# tviic2d6mddr register map
Vendor: Cypress Semiconductor; Series: tviic2d6mddr; File version: 1.0
CPU: CM7 r0p1, little endian, MPU, FPU, VTOR, 3 interrupt priority bits
Registers are 32-bit, read-write, reset 0x0 unless marked. A register's access mark holds for its fields unless they carry their own. Offsets are from the block's base; [hi:lo] are bit positions; lines under a group give offsets from that group; {n}, {i} and the like mark numbered series; 'fields as' and 'values as' point back to an identical list; <NAME> marks a mode.

## MIXER0 — MIXER
Base 0x40880000
Same registers: MIXER1 0x40890000
{0x8000+0x100*i} MIXER_SRC_STRUCT[{i}] (i=0..4) group — Mixer source structure
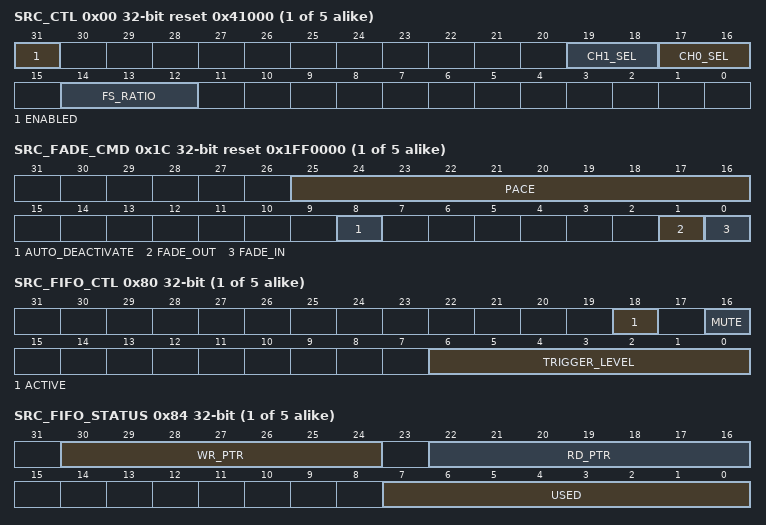
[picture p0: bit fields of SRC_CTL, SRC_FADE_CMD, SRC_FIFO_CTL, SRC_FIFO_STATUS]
  0x00 SRC_CTL reset 0x41000 — Source control
    [31] ENABLED — Source enable: '0': Disabled. All non-retained MMIO registers (e.g. the SRC_STATUS, SRC_FIFO_STATUS and INTR_SRC registers) have their fields reset to their default value. '1': Enabled. Note: when all sources, destination and transmitter are disabled, the SRAMs are driven into low power mode, if supported by the SRAM. When exiting such low power mode software needs to allow for a certain power up time before SRAM can be used, i.e. before ACTIVE can be asserted. The power up time is equivalent to the system SRAM power up time specified in the CPUSS.RAM_PWR_DELAY_CTL register (or equivalent for platforms other than MXS40).
    [19:18] CH1_SEL — Channel selection. Specifies selection of the channel's 16-bit PCM data from the source FIFO data[31:0]: '0': data[15:0]. '1': data[31:16] (default setting). '2': Constant PCM data value of '0'; i.e. source FIFO data is not used. '3': undefined.
      0=DATA_LOW (N/A); 1=DATA_HIGH (N/A); 2=CONSTANT_0 (N/A)
    [17:16] CH0_SEL — Channel selection. Specifies selection of the channel's 16-bit PCM data from the source FIFO data[31:0]: '0': data[15:0] (default setting). '1': data[31:16]. '2': Constant PCM data value of '0'; i.e. source FIFO data is not used. '3': undefined. Note: CH0_SEL and CH1_SEL are used to specify mono and stereo audio formats.
      0=DATA_LOW (N/A); 1=DATA_HIGH (N/A); 2=CONSTANT_0 (N/A)
    [14:12] FS_RATIO — Sample frequency upscale ratio: '0': 0.5 (downsampling by 2x). '1': 1 (no resampling). '2': 2 (upsampling by 2x). '3': 3. '4': 4. '5': 6. '6': 8. '7': 12 (upsampling by 12x).
      0=DOWN_2 (N/A); 1=SAME (N/A); 2=UP_2 (N/A); 3=UP_3 (N/A); 4=UP_4 (N/A); 5=UP_6 (N/A); 6=UP_8 (N/A); 7=UP_12 (N/A)
  0x04 SRC_STATUS ro — Source status
    [3:0] PHASE — Current FIR phase value. A upscale ratio of 'n' uses a n polyphase FIR filter. The phases are numbered [0, n-1].
      0=N/A; 1=N/A; 11=N/A
  0x14 SRC_FADE_CTL reset 0x73 — Source fade control
    [6:0] CODE — Gain code in the range [0, 115]. See SRC_GAIN_CTL.CODE[]. Note: HW modifies this field during 'fade in' and 'fade out'. For 'fade in' HW will gradually increment the value until it reaches '115'. For 'fade out' HW will gradually decrement the value until it reaches '0'. Note: SW is typically required to reprogram the CODE field in between successive 'fade in' operations or in between successive 'fade out' operations.
  0x18 SRC_FADE_STATUS ro reset not defined — Source fade status
    [25:16] PACE — Current fading pace counter value. SRC_FADE_CTL.PACE value of 'n' reuses a specific fade value 'n+1' times. The reuses are numbered [0, n].
  0x1C SRC_FADE_CMD reset 0x1FF0000 — Source fade command
    [25:16] PACE — Specifies the pace/speed of 'fade in' and 'fade out': '0': The same CODE value is used (0+1) times. '1': The same CODE value is used (1+1) times. ... '1023': The same CODE value is used (1023+1) times. A fade in from 'mute' to 0 dB takes 1024*116 = 118,784 PCM samples. At a PCM sample frequency Fs of 48 kHz, this translates into 118,784/48,000 = 2.474 seconds.
    [8] AUTO_DEACTIVATE — Specifies behavior when 'fade out' has completed: '0': Source does NOT get deactivated. '1': Source gets deactivated; i.e. HW clears SRC_FIFO_CTL.ACTIVE to '0'.
    [1] FADE_OUT — 'Fade out' functionality: '0': Disabled. '1': Enabled: Changes CODE gradually to '0' (digital mute). Typically, SW sets this field to '1' to start 'fade out' functionality. HW clears this field to '0' to indicate that 'fade out' has completed; i.e. 'muting' is achieved. Note: FADE_IN and FADE_OUT should be used mutually exclusively. However, if 'fade in' is desired while 'fading out', SW can set FADE_IN to '1' and clear FADE_OUT to '0'. 'Fade in' will commence from the current CODE value. Similarly, if 'fade out' is desired while 'fading in', SW can set FADE_OUT to '1' and clear FADE_IN to '0'. 'Fade out' will commence from the current CODE value.
    [0] FADE_IN — 'Fade in' functionality: '0': Disabled. '1': Enabled: Increments CODE gradually to '115'. Typically, SW sets this field to '1' to start 'fade in' functionality. HW clears this field to '0' to indicate that 'fade in' has completed; i.e. 0 dB amplification is achieved.
  0x20 SRC_GAIN_CTL reset 0x73 — Source gain control
    [6:0] CODE — Gain code in the range [0, 127]. Each gain code increment represents 1 dB. Gain code value '0' represents digital mute. Gain code '127' represents a maximum amplification of 12 dB. The gain code is used to derive a multipler value (in the range [0, 8191]) and shift value (in the range [11, 26]). '0': digital mute. Multiplier value is '0' and 'shift' is '26'. '1': -114 dB. Multiplier value is '134' and 'shift' is '26'. '2': -113 dB. Multiplier value is '150' and 'shift' is '26'. '3': -112 dB. Multiplier value is '169' and 'shift' is '26'. ... '115': 0 dB. Multiplier value is '4096' and 'shift' is '12'. Note that (4096 * x) >> 12 = x; i.e. the PCM value is unaffected. ... '121': 6 dB. Multiplier value is '8173' and 'shift' is '12'. ... '127': 12 dB. Multiplier value is '8153' and 'shift' is '11'. gc_pcm[15:0] = CLIP16 ((multiplier[12:0]*fir_scaled_pcm[15:0]) >> shift)
  0x80 SRC_FIFO_CTL — Source FIFO control
    [18] ACTIVE — Activate functionality: '0': Mixer source inactive; i.e. use PCM data value of '0'. '1': Mixer source active; i.e. use FIFO PCM data, when PCM data are not available: wait. HW clears this field to '0' when fading out has completed and SRC_FADE_CMD.AUTO_DEACTIVATE is '1'. Note: This functionality is intended for startup purposes. To start the mixer, SW should first activate the sources(s) and second activate the destination. To stop the mixer, SW should first deactivate the destination and second deactivate the source(s).
    [16] MUTE — Mute functionality: '0': Mixer source unmuted; i.e. source FIFO data. '1': Mixer source muted; i.e. use PCM data value of '0'. Mute does advance the FIFO read pointer. Note: HW ensures that mute functionality synchronizes on the first channel of a frame to ensure that either all or none of the frame's channels are muted.
    [6:0] TRIGGER_LEVEL — Trigger level. When the source FIFO has less entries than the number of this field, a transmitter trigger event is generated: - INTR_SRC.FIFO_TRIGGER = (# FIFO entries < TRIGGER_LEVEL)
  0x84 SRC_FIFO_STATUS ro — Source FIFO status
    [30:24] WR_PTR — Source FIFO write pointer: Source FIFO location at which a new data is written by the hardware. Note: This functionality is intended for debugging purposes.
    [22:16] RD_PTR — Source FIFO read pointer: Source FIFO location from which a data is read. Note: This functionality is intended for debugging purposes.
    [7:0] USED — Number of used/occupied entries in the source FIFO. The field value is in the range [0, 128]. When '0', the FIFO is empty. When '128', the FIFO is full. Note: A source FIFO has double the capacity of the destination FIFO. This is because the sample frequency conversion requires 63 PCM input samples to produce a PCM output sample (63-taps FIR filter).
  0x88 SRC_FIFO_WR wo — Source FIFO write
    [31:0] DATA — Data (PCM sample pair of two 16-bit samples) written to the top source FIFO entry (data[31:0] = DATA[31:0]). Typically, DATA[15:0] is used for channel 0 and DATA[31:16] is used for channel 1. Writing adds the data to the source FIFO; i.e. behavior is similar to that of a PUSH operation (SRC_FIFO_STATUS.WR_PTR is incremented and SRC_FIFO_STATUS.USED is incremented). Note: Writing to a full source FIFO activates INTR_SRC.FIFO_OVERFLOW.
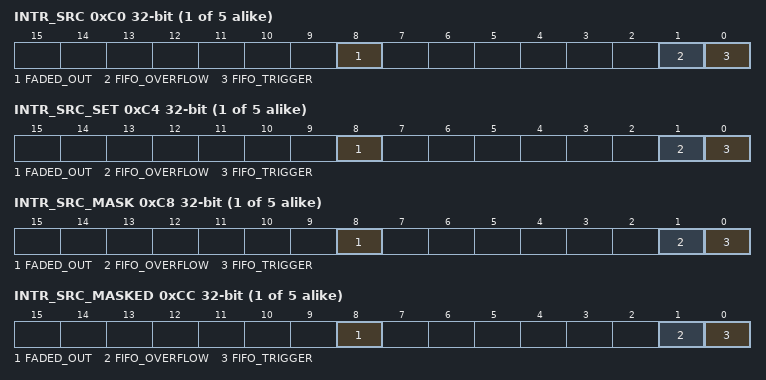
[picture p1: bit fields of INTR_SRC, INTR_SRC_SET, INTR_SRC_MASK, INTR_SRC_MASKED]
  0xC0 INTR_SRC — Interrupt
    [8] FADED_OUT — HW sets this field to '1', when fade out has completed (HW changes SRC_FADE_CMD.FADE_OUT from '0' to '1').
    [1] FIFO_OVERFLOW — HW sets this field to '1', when writing to a full source FIFO (SRC_FIFO_STATUS.USED is '128').
    [0] FIFO_TRIGGER — HW sets this field to '1', when a source trigger is generated.
  0xC4 INTR_SRC_SET — Interrupt set
    [8] FADED_OUT — Write this field with '1' to set corresponding INTR_SRC field (a write of '0' has no effect).
    [1] FIFO_OVERFLOW — Write this field with '1' to set corresponding INTR_SRC field (a write of '0' has no effect).
    [0] FIFO_TRIGGER — Write this field with '1' to set corresponding INTR_SRC field (a write of '0' has no effect).
  0xC8 INTR_SRC_MASK — Interrupt mask
    [8] FADED_OUT — Mask for corresponding field in INTR_SRC register.
    [1] FIFO_OVERFLOW — Mask for corresponding field in INTR_SRC register.
    [0] FIFO_TRIGGER — Mask for corresponding field in INTR_SRC register.
  0xCC INTR_SRC_MASKED ro — Interrupt masked
    [8] FADED_OUT — Logical AND of corresponding INTR_SRC and INTR_SRC_MASK fields.
    [1] FIFO_OVERFLOW — Logical AND of corresponding INTR_SRC and INTR_SRC_MASK fields.
    [0] FIFO_TRIGGER — Logical AND of corresponding INTR_SRC and INTR_SRC_MASK fields.
0xC000 MIXER_DST_STRUCT group — Mixer destination structure
  0x00 DST_CTL — Destination control
    [31] ENABLED — Destination enable: '0': Disabled. All non-retained MMIO registers (e.g. the DST_FADE_STATUS, DST_FIFO_STATUS and INTR_DST registers) have their fields reset to their default value. '1': Enabled. Note: when all sources, destination and transmitter are disabled, the SRAMs are driven into low power mode, if supported by the SRAM. When exiting such low power mode software needs to allow for a certain power up time before SRAM can be used, i.e. before ACTIVE can be asserted. The power up time is equivalent to the system SRAM power up time specified in the CPUSS.RAM_PWR_DELAY_CTL register (or equivalent for platforms other than MXS40).
  0x14 DST_FADE_CTL reset 0x73 — Destination fade control
    [6:0] CODE — Gain code in the range [0, 115]. See DST_GAIN_CTL.CODE[]. Note: HW modifies this field during 'fade in' and 'fade out'. For 'fade in' HW will gradually increment the value until it reaches '115'. For 'fade out' HW will gradually decrement the value until it reaches '0'. Note: SW is typically required to reprogram the CODE field in between successive 'fade in' operations or in between successive 'fade out' operations.
  0x18 DST_FADE_STATUS ro reset not defined — Destination fade status
    [25:16] PACE — Current fading pace counter value. DST_FADE_CTL.PACE value of 'n' reuses a specific fade value 'n+1' times. The reuses are numbered [0, n].
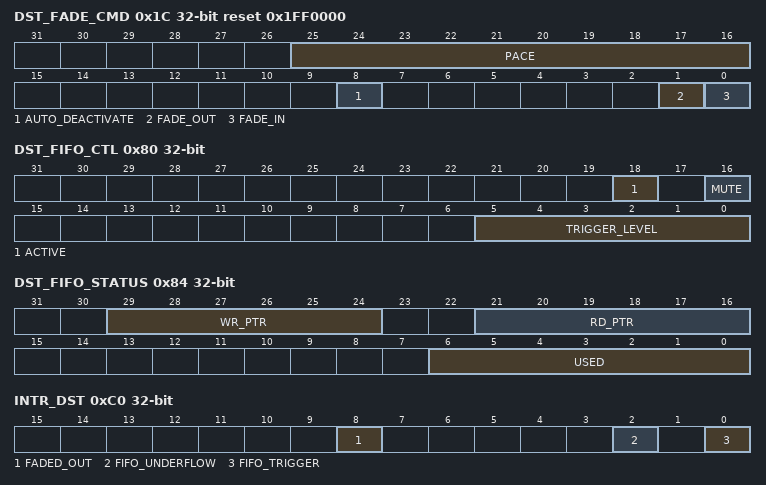
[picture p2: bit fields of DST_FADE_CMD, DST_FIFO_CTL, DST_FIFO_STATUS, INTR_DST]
  0x1C DST_FADE_CMD reset 0x1FF0000 — Destination fade command
    [25:16] PACE — Specifies the pace/speed of 'fade in' and 'fade out': '0': The same CODE value is used (0+1) times. '1': The same CODE value is used (1+1) times. ... '1023': The same CODE value is used (1023+1) times. A fade in from 'mute' to 0 dB takes 1024*116 = 118,784 PCM samples. At a PCM sample frequency Fs of 48 kHz, this translates into 118,784/48,000 = 2.474 seconds.
    [8] AUTO_DEACTIVATE — Specifies behavior when 'fade out' has completed: '0': Destination does NOT get deactivated. '1': Destination gets deactivated; i.e. HW clears DST_FIFO_CTL.ACTIVE to '0'.
    [1] FADE_OUT — 'Fade out' functionality: '0': Disabled. '1': Enabled: Changes CODE gradually to '0' (digital mute). Typically, SW sets this field to '1' to start 'fade out' functionality. HW clears this field to '0' to indicate that 'fade out' has completed; i.e. 'muting' is achieved. Note: FADE_IN and FADE_OUT should be used mutually exclusively. However, if 'fade in' is desired while 'fading out', SW can set FADE_IN to '1' and clear FADE_OUT to '0'. 'Fade in' will commence from the current CODE value. Similarly, if 'fade out' is desired while 'fading in', SW can set FADE_OUT to '1' and clear FADE_IN to '0'. 'Fade out' will commence from the current CODE value.
    [0] FADE_IN — 'Fade in' functionality: '0': Disabled. '1': Enabled: Increments CODE gradually to '115'. Typically, SW sets this field to '1' to start 'fade in' functionality. HW clears this field to '0' to indicate that 'fade in' has completed; i.e. 0 dB amplification is achieved.
  0x20 DST_GAIN_CTL reset 0x73 — Destination gain control
    fields as MIXER_SRC_STRUCT[0].SRC_GAIN_CTL
  0x80 DST_FIFO_CTL — Destination FIFO control
    [18] ACTIVE — Activate functionality: '0': Mixer destination off; i.e. no PCM data produced. '1': Mixer destination on; i.e. PCM data produced. Note: This functionality is intended for stopping purposes. To start the mixer, SW should first activate the sources(s) and second activate the destination. To stop the mixer, SW should first deactivate the destination and second deactivate the source(s).
    [16] MUTE — Mute functionality: '0': Mixer destination unmuted; i.e. use mixed PCM data. '1': Mixer destination muted; i.e. use PCM data value of '0'. Mute does advance the FIFO write pointer. Note: HW ensures that mute functionality synchronizes on the first channel of a frame to ensure that either all or none of the frame's channels are muted.
    [5:0] TRIGGER_LEVEL — Trigger level. When the destination FIFO has more entries than the number of this field, a receiver trigger event is generated: - INTR_DST.FIFO_TRIGGER = (# FIFO entries > TRIGGER_LEVEL)
      0=EMPTY (N/A); 1=USED_1 (N/A); 63=USED_63 (N/A)
  0x84 DST_FIFO_STATUS ro — Destination FIFO status
    [29:24] WR_PTR — Destination FIFO write pointer: Destination FIFO location at which a new data is written by the hardware. Note: This functionality is intended for debugging purposes.
    [21:16] RD_PTR — Destination FIFO read pointer: Destination FIFO location from which a data is read. Note: This functionality is intended for debugging purposes.
    [6:0] USED — Number of used/occupied entries in the destination FIFO. The field value is in the range [0, 64]. When '0', the FIFO is empty. When '64', the FIFO is full.
  0x88 DST_FIFO_RD ro — Destination FIFO read
    [31:0] DATA — Data (PCM sample pair) read from the top destination FIFO entry (DATA[31:0] = {ch1_data[15:0], ch0_data[15:0]). Reading removes the data from the destination FIFO; i.e. behavior is similar to that of a POP operation (DST_FIFO_STATUS.RD_PTR is incremented and DST_FIFO_STATUS.USED is decremented). Note: Reading from an empty destination FIFO activates INTR_DST.FIFO_UNDERFLOW (if DST_CTL.ENABLED is '1' and TX_CTL.ENABLED is ''0').
  0x8C DST_FIFO_RD_SILENT ro — Destination FIFO silent read
    [31:0] DATA
  0xC0 INTR_DST — Interrupt
    [8] FADED_OUT — HW sets this field to '1', when fading out has completed (HW changes DST_FADE_CMD.FADE_OUT from '0' to '1').
    [2] FIFO_UNDERFLOW — HW sets this field to '1', when reading from an empty destination FIFO (DST_FIFO_STATUS.USED is '0').
    [0] FIFO_TRIGGER — HW sets this field to '1', when a destination trigger is generated.
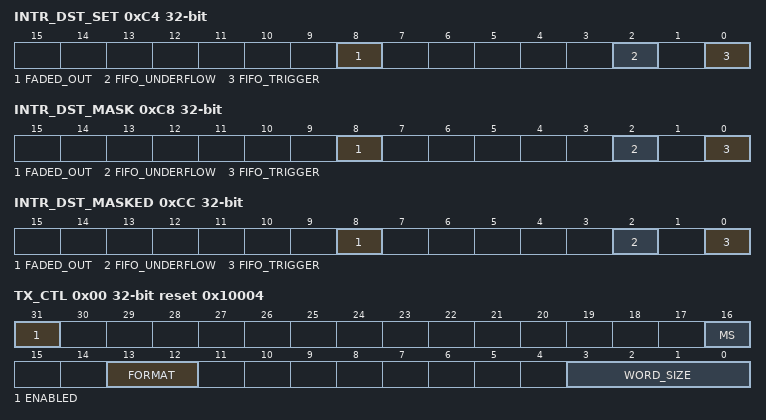
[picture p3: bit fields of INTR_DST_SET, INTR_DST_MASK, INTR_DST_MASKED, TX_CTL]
  0xC4 INTR_DST_SET — Interrupt set
    [8] FADED_OUT — Write this field with '1' to set corresponding INTR_DST field (a write of '0' has no effect).
    [2] FIFO_UNDERFLOW — Write this field with '1' to set corresponding INTR_DST field (a write of '0' has no effect).
    [0] FIFO_TRIGGER — Write this field with '1' to set corresponding INTR_DST field (a write of '0' has no effect).
  0xC8 INTR_DST_MASK — Interrupt mask
    [8] FADED_OUT — Mask for corresponding field in INTR_DST register.
    [2] FIFO_UNDERFLOW — Mask for corresponding field in INTR_DST register.
    [0] FIFO_TRIGGER — Mask for corresponding field in INTR_DST register.
  0xCC INTR_DST_MASKED ro — Interrupt masked
    [8] FADED_OUT — Logical AND of corresponding INTR_DST and INTR_DST_MASK fields.
    [2] FIFO_UNDERFLOW — Logical AND of corresponding INTR_DST and INTR_DST_MASK fields.
    [0] FIFO_TRIGGER — Logical AND of corresponding INTR_DST and INTR_DST_MASK fields.
0xD000 MIXER_TX_STRUCT group — Mixer TX structure
  0x00 TX_CTL reset 0x10004 — TX control
    [31] ENABLED — Transmitter (TX) enable: '0': Disabled. All non-retained MMIO registers (e.g. the TX_FIFO_STATUS and INTR_TX registers) have their fields reset to their default value. '1': Enabled. Note: when all sources, destination and transmitter are disabled, the SRAMs are driven into low power mode, if supported by the SRAM. When exiting such low power mode software needs to allow for a certain power up time before SRAM can be used, i.e. before ACTIVE can be asserted. The power up time is equivalent to the system SRAM power up time specified in the CPUSS.RAM_PWR_DELAY_CTL register (or equivalent for platforms other than MXS40).
    [16] MS — Master/slave setting: '0': Slave. - External transmitter 'mixer_tx_sck_in' and transmitter 'mixer_tx_ws_in'. '1': Master. - Interface clock 'clk_if' is used to generate transmitter 'mixer_tx_sck_out' and transmitter 'mixer_tx_ws_out'.
      0=SLAVE (N/A); 1=MASTER (N/A)
    [13:12] FORMAT — Format: '0': Left-aligned delayed (I2S). '1': Left-aligned. '2': Right-aligned delayed. '3': Right-aligned.
      0=LEFT_DELAYED (N/A); 1=LEFT (N/A); 2=RIGHT_DELAYED (N/A); 3=RIGHT (N/A)
    [3:0] WORD_SIZE ro — PCM word size: '0'-'3': Undefined. '4': 16 bit. The IP always uses 16-bit PCM words. '9'-'15': Undefined.
      4=SIZE_16 (N/A)
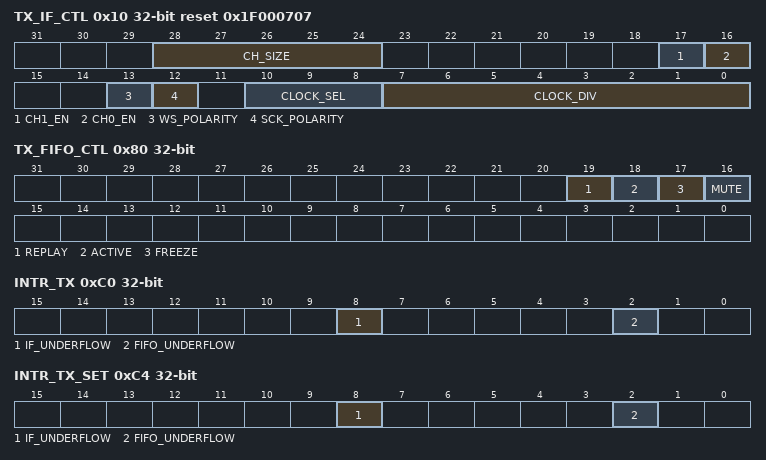
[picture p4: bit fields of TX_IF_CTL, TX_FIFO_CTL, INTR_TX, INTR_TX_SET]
  0x10 TX_IF_CTL reset 0x1F000707 — TX interface control
    [28:24] CH_SIZE — Channel size: '0': 1 bit. '1': 2 bits. ... '31': 32 bits. Note: channel size must be greater or equal to the word size.
      0=SIZE_1 (N/A); 1=SIZE_2 (N/A); 31=SIZE_32 (N/A)
    [17] CH1_EN — Channel 1 enable: '0': Disabled. The TX FIFO does not produce channel 1 words and 'mixer_tx_sd_out' is not driven. '1': Enabled.
    [16] CH0_EN — Channel 0 enable: '0': Disabled. The TX FIFO does not produce channel 0 words and 'mixer_tx_sd_out' is not driven. '1': Enabled.
    [13] WS_POLARITY — Word select polarity: '0': Word select signal is used 'as is'. '1': Word select signal is inverted. Note: Used in BOTH master and slave configurations.
    [12] SCK_POLARITY — Clock polarity: '0': Clock signal is used 'as is'. '1': Clock signal is inverted. Note: Used in BOTH master and slave configurations.
    [10:8] CLOCK_SEL — Interface clock 'clk_if' selection: '0': SRSS clock clk_if_srss. '1'-'3': undefined. '4': Master interface clock 'mixer_tx_mck_in'. '5'-'7': undefined. Note: the application is always required to program this field to a value different from the default.
      0=SEL_SRSS_CLOCK (N/A); 4=SEL_MIXER_TX_MCK_IN (N/A)
    [7:0] CLOCK_DIV — Interface clock divider (legal range [1, 255]). The I2S interface 'i2s_tx_sck_out' output signal is defined as clk_if / (CLOCK_DIV + 1). CLOCK_DIV should be set to an odd value ({1, 3, 5, ..., 255}), to ensure a 50/50 percent duty cycle clock. Note: Used in master configuration only.
  0x80 TX_FIFO_CTL — TX FIFO control
    [19] REPLAY — Replay functionality (used when FREEZE is '1' or in case of a FIFO underflow event): '0': HW uses a constant PCM data value of '0'. '1': HW uses the previous PCM data value.
    [18] ACTIVE — Activate functionality: '0': Transmitter off. The FIFO_UNDERFLOW interrupt cause will not be activated. '1': Transmitter on. The FIFO_UNDERFLOW interrupt may be activated (when an underflow event occurs). Note: This functionality is intended for startup purposes.
    [17] FREEZE — Freeze functionality: '0': HW uses destination (TX) FIFO data and advances the FIFO read pointer. '1': HW uses a constant PCM data value of '0' or the previous channel PCM data is replayed. Freeze does not advance the FIFO read pointer (the FIFO data is not used). Note: HW ensures that freeze functionality synchronizes on the first channel of a frame to ensure that PCM data of one channel is not misassigned to another channel. As a result, the freeze functionality can be activated at any time. Note: This functionality is intended for debugging purposes.
    [16] MUTE — Mute functionality: '0': HW uses destination (TX) FIFO data. '1': HW uses a constant PCM data value of '0'. Mute does advance the FIFO read pointer. Note: HW ensures that mute functionality synchronizes on the first channel of a frame to ensure that either all or none of the frame's channels are muted.
  0xC0 INTR_TX — Interrupt
    [8] IF_UNDERFLOW — HW sets this field to '1', when PCM samples are not generated in time for the interface logic (interface underflow). This may be an indication that the IP system frequency is too low wrt. the interface frequency (a SW configuration error). The interface underflow is a non-recoverable error and requires SW disabling of the channel (a SW write to INTR_TX.IF_UNDERFLOW does not resolve the interface underflow). Note: This functionality is intended for debug purposes.
    [2] FIFO_UNDERFLOW — HW sets this field to '1', when reading from an empty destination (TX) FIFO (DST_FIFO_STATUS.USED == 0). This is referred to as an underflow event. Note: HW ensures that either all or none of the frame's channels are transmitted. In a FIFO underflow situation, HW replays previous PCM data or uses a constant PCM data value of '0'.
  0xC4 INTR_TX_SET — Interrupt set
    [8] IF_UNDERFLOW — Write this field with '1' to set corresponding INTR_TX field (a write of '0' has no effect).
    [2] FIFO_UNDERFLOW — Write this field with '1' to set corresponding INTR_TX field (a write of '0' has no effect).
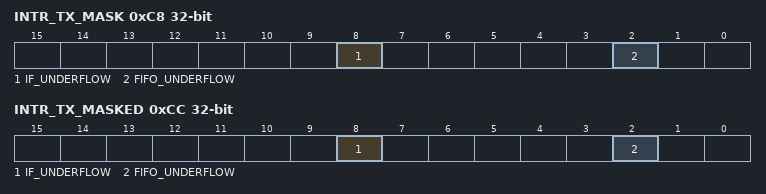
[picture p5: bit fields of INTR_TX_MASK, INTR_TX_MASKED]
  0xC8 INTR_TX_MASK — Interrupt mask
    [8] IF_UNDERFLOW — Mask for corresponding field in INTR_TX register.
    [2] FIFO_UNDERFLOW — Mask for corresponding field in INTR_TX register.
  0xCC INTR_TX_MASKED ro — Interrupt masked
    [8] IF_UNDERFLOW — Logical AND of corresponding INTR_TX and INTR_TX_MASK fields.
    [2] FIFO_UNDERFLOW — Logical AND of corresponding INTR_TX and INTR_TX_MASK fields.
